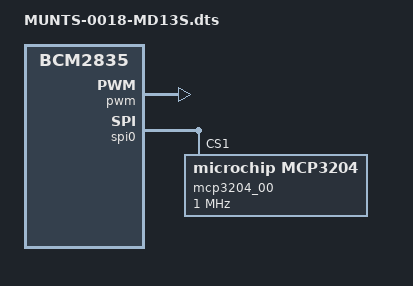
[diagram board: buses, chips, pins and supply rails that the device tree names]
// Device tree overlay for the MUNTS-0018 Raspberry Pi Tutorial I/O Board
// attached to a Raspberry Pi Zero, Zero W, or Zero 2 W.

/dts-v1/;
/plugin/;

/ {
	compatible = "brcm,bcm2835";

	// Enable PWM0 on GPIO18 and PWM1 on GPI13

	fragment@0 {
		target = <&gpio>;
		__overlay__ {
			pwm_pins: pwm_pins {
				brcm,pins = <18 13>;
				brcm,function = <2 4>; /* ALT5 ALT0 */
			};
		};
	};

	fragment@1 {
		target = <&pwm>;
		frag1: __overlay__ {
			pinctrl-names = "default";
			pinctrl-0 = <&pwm_pins>;
			assigned-clock-rates = <100000000>;
			status = "okay";
		};
	};

	__overrides__ {
		pin   = <&pwm_pins>,"brcm,pins:0";
		func  = <&pwm_pins>,"brcm,function:0";
		clock = <&frag1>,"assigned-clock-rates:0";
	};

	// Enable MCP3204 on GPIO7

	fragment@2 {
		target = <&spi0>;
		__overlay__ {
			#address-cells = <1>;
			#size-cells = <0>;
			status = "okay";

			mcp3204_00: mcp3204@1{
				compatible = "microchip,mcp3204";
				reg = <1 1>;
				spi-max-frequency = <1000000>;
				status = "okay";
			};
		};
	};
};
